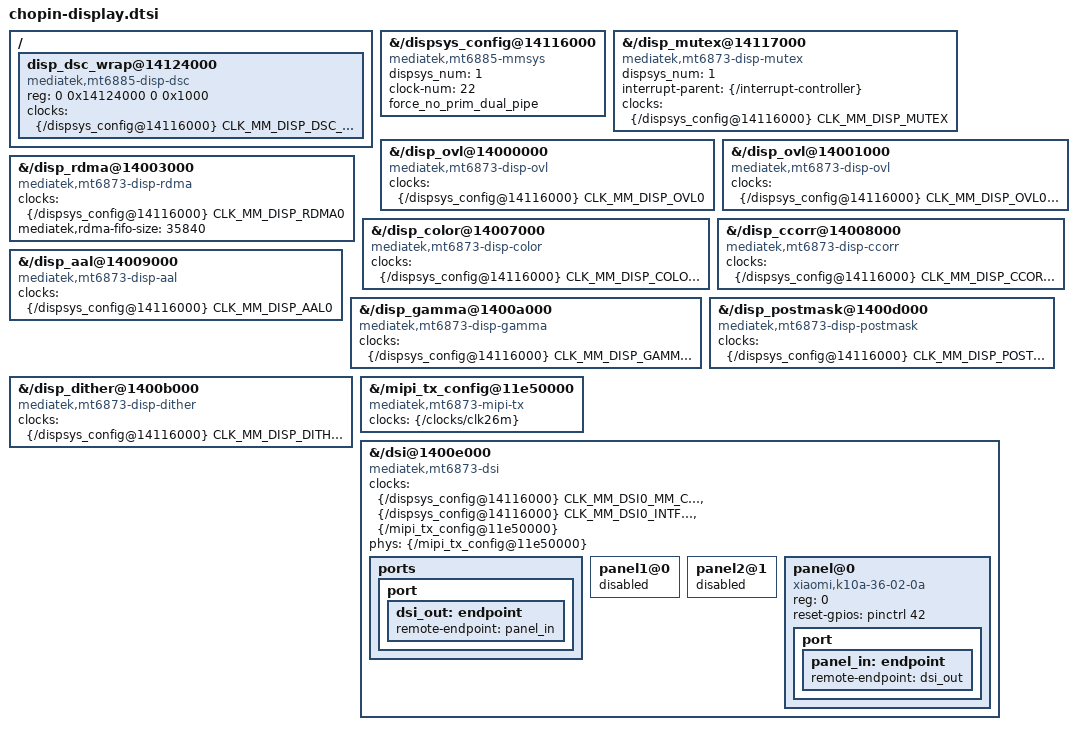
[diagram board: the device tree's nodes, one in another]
// SPDX-License-Identifier: GPL-2.0-only
/*
 * chopin: the display pipeline, CRTC0.
 */

&{/dispsys_config@14116000} {
	compatible = "mediatek,mt6885-mmsys", "mediatek,mt6893-disp", "mediatek,mt6873-mmsys",
		     "mediatek,mt6893-mmsys", "syscon";
	dispsys_num = <1>;
	/* the v2 master reads this to size its top-clock list (their mt6895.dtsi uses 22) */
	clock-num = <22>;

	/*
	 * Force the primary path to a single pipe.
	 *
	 * The live base tree carries the vendor's helper-name/helper-value
	 * arrays, and the last entry is
	 * "MTK_DRM_OPT_PRIM_DUAL_PIPE" with value 1.  With that option set,
	 * mtk_crtc_is_dual_pipe() turns dual pipe on as soon as the panel
	 * reports output_mode == MTK_PANEL_DSC_SINGLE_PORT with slice_mode 1 -
	 * which is exactly this panel - and the CRTC then walks the second
	 * path (OVL1, RDMA1, COLOR1, CCORR1, AAL1, GAMMA1, POSTMASK1,
	 * DITHER1).  None of those blocks exists on this board: they are the
	 * MT6895-only nodes this tree disables, so the walk dereferences
	 * unbound DDP components and the first modeset wedges (observed as
	 * is_dual_pipe=1, and as /proc/fb blocking because register_framebuffer
	 * never returns).
	 *
	 * The v2 stack has a purpose-built override for this: when
	 * force_no_prim_dual_pipe is present, mtk_drm_helper.c explicitly
	 * clears MTK_DRM_OPT_PRIM_DUAL_PIPE after parsing the arrays.
	 */
	force_no_prim_dual_pipe;
};

&{/disp_mutex@14117000} {
	compatible = "mediatek,mt6873-disp-mutex";
	dispsys_num = <1>;
	interrupt-parent = <&{/interrupt-controller}>;
	clocks = <&{/dispsys_config@14116000} CLK_MM_DISP_MUTEX>;
};

&{/disp_ovl@14000000} {
	compatible = "mediatek,mt6873-disp-ovl";
	clocks = <&{/dispsys_config@14116000} CLK_MM_DISP_OVL0>;
};

&{/disp_ovl@14001000} {
	compatible = "mediatek,mt6873-disp-ovl";
	clocks = <&{/dispsys_config@14116000} CLK_MM_DISP_OVL0_2L>;
};

&{/disp_rdma@14003000} {
	compatible = "mediatek,mt6873-disp-rdma";
	clocks = <&{/dispsys_config@14116000} CLK_MM_DISP_RDMA0>;
	/* The vendor data for this SoC says 3 KiB + 32 KiB; the mt8183
	 * fallback data would otherwise leave the driver with 5 KiB, which
	 * only lowers the FIFO underflow threshold (visible as tearing). */
	mediatek,rdma-fifo-size = <35840>;
};

&{/disp_color@14007000} {
	compatible = "mediatek,mt6873-disp-color";
	clocks = <&{/dispsys_config@14116000} CLK_MM_DISP_COLOR0>;
};

&{/disp_ccorr@14008000} {
	compatible = "mediatek,mt6873-disp-ccorr";
	clocks = <&{/dispsys_config@14116000} CLK_MM_DISP_CCORR0>;
};

&{/disp_aal@14009000} {
	compatible = "mediatek,mt6873-disp-aal";
	clocks = <&{/dispsys_config@14116000} CLK_MM_DISP_AAL0>;
};

&{/disp_gamma@1400a000} {
	compatible = "mediatek,mt6873-disp-gamma";
	clocks = <&{/dispsys_config@14116000} CLK_MM_DISP_GAMMA0>;
};

&{/disp_postmask@1400d000} {
	compatible = "mediatek,mt6873-disp-postmask";
	clocks = <&{/dispsys_config@14116000} CLK_MM_DISP_POSTMASK0>;
};

&{/disp_dither@1400b000} {
	compatible = "mediatek,mt6873-disp-dither";
	clocks = <&{/dispsys_config@14116000} CLK_MM_DISP_DITHER0>;
};

/*
 * DSC wrap.  The bootloader programs and runs it (port/DSC-REFERENCE.md holds
 * the register values read back from that live instance); this node lets our
 * own driver bind to it so we can take the encoder over.
 *
 * The live base tree already carries this node and it is right about almost
 * everything: it names "mediatek,disp_dsc_wrap", "mediatek,mt6885-disp-dsc" -
 * the same DSC the vendor MT6893 tree declares for this address - and it
 * carries the GIC_SPI 281 interrupt, which mtk_disp_dsc_probe() cannot start
 * without (platform_get_irq() there is mandatory, not optional).
 *
 * An earlier version of this override renamed the compatible to
 * "mediatek,mt6893-disp-dsc".  That string matches neither the v2 DSC
 * driver's of_match nor mtk_drm_drv.c's component table, so the block never
 * probed and never entered the pipeline - which is why the DSC encoder was
 * missing from the bound-component list.  There is no mt6893-specific DSC
 * data in this stack and the vendor tree does not use one either: this board's
 * DSC is the mt6885 revision, which is also what the dispsys node selects
 * (its first compatible is mediatek,mt6885-mmsys -> MMSYS_MT6885, and
 * mtk_drm_crtc.c dispatches DSC insertion on exactly that id).
 *
 * So only the clock needs restating here: CLK_MM_DISP_DSC_WRAP (44) is our
 * clock driver's numbering, while the base tree's raw index 43 belongs to the
 * vendor binding.  reg and interrupts are inherited unchanged.
 */
/ {
	disp_dsc_wrap@14124000 {
		compatible = "mediatek,mt6885-disp-dsc";
		reg = <0 0x14124000 0 0x1000>;
		clocks = <&{/dispsys_config@14116000} CLK_MM_DISP_DSC_WRAP>;
	};
};

/*
 * MIPI D-PHY.  Mainline's mt8183 mipi-tx data drives this PHY: the register
 * map, the divider thresholds and the PLL formula are identical, and the
 * binding lists mediatek,mt6893-mipi-tx with mediatek,mt8183-mipi-tx as the
 * fallback.  Only the compatible and the reference clock need restating (the
 * fixed 26 MHz clock, not the vendor's clock phandle).
 */
&{/mipi_tx_config@11e50000} {
	compatible = "mediatek,mt6873-mipi-tx";
	clocks = <&{/clocks/clk26m}>;
};

&{/dsi@1400e000} {
	compatible = "mediatek,mt6873-dsi";
	clocks = <&{/dispsys_config@14116000} CLK_MM_DSI0_MM_CLK>,
		 <&{/dispsys_config@14116000} CLK_MM_DSI0_INTF_CLK>,
		 <&{/mipi_tx_config@11e50000}>;
	clock-names = "engine", "digital", "hs";
	phys = <&{/mipi_tx_config@11e50000}>;
	phy-names = "dphy";

	/*
	 * Single DSI: the panel hangs off port 0, and there must be NO port 1.
	 *
	 * Two different lookups use these ports, and an earlier version of this
	 * file had them the wrong way round:
	 *
	 *   - mtk_dsi_probe() resolves the panel with
	 *     of_graph_get_next_endpoint(), i.e. the FIRST endpoint - port 0.
	 *     The vendor tree's port 0 points at panel1@0, whose compatible
	 *     ("k10a_36_02_0a_dsc_vdo,lcm") has no driver in this kernel and
	 *     which our own override below disables - so of_drm_find_panel()
	 *     answered -ENODEV and dsi->panel/dsi->ext stayed NULL.  That alone
	 *     gave the connector DRM's generic 1024x768/800x600 fallback modes
	 *     and made the first modeset NULL-dereference in
	 *     mtk_dsi_ps_control_vact().
	 *
	 *   - dsi_find_slave() looks for a DUAL-DSI companion with
	 *     of_graph_get_remote_node(node, 1, 0) - port 1 - and returns
	 *     -EPROBE_DEFER when that node exists but is not a bound platform
	 *     device.  With our panel parked on port@1 it was mistaken for the
	 *     slave: mtk_dsi_host_attach() failed, mipi_dsi_attach() failed, and
	 *     lcm_probe() then called drm_panel_remove() - deleting the panel
	 *     from the very list mtk_dsi_probe() was about to search.  That is
	 *     why "drm_panel_add done" printed and the lookup still found
	 *     nothing.
	 *
	 * So: repoint the vendor's port 0 at the panel we actually drive and
	 * drop port 1 entirely.
	 */
	ports {
		#address-cells = <1>;
		#size-cells = <0>;

		/delete-node/ port@1;

		port {
			dsi_out: endpoint {
				remote-endpoint = <&panel_in>;
			};
		};
	};

	/*
	 * The vendor's panel@0/@1 children are left disabled: their
	 * compatible strings match no mainline driver and only channel 0
	 * (this node) is driven.
	 */
	panel1@0 {
		status = "disabled";
	};

	panel2@1 {
		status = "disabled";
	};

	panel@0 {
		compatible = "xiaomi,k10a-36-02-0a";
		reg = <0>;

		reset-gpios = <&{/pinctrl} 42 GPIO_ACTIVE_HIGH>;
		/* DVDD (WL2866D) and AVDD/AVEE (LM36273) have no mainline
		 * driver yet; the bootloader leaves both rails on. */
		status = "okay";

		port {
			panel_in: endpoint {
				remote-endpoint = <&dsi_out>;
			};
		};
	};
};

/*
 * The v2 master enumerates every display node in the DT and waits for each one
 * to probe; these are MT6895/MT8195-family blocks that our board does not
 * use (their naming comes from the upstream chopin DTS).  Disable them so the
 * component list is the set this SoC actually drives.
 */
